# ESP32-S31 register map
Vendor: ESPRESSIF SYSTEMS (SHANGHAI) CO., LTD.; Series: ESP32 S-Series; File version: 1
CPU: RV32IMAFC r0p0, little endian, no MPU, FPU, 0 interrupt priority bits
Address unit: 32 bits
Registers are 32-bit, read-write, reset 0x0 unless marked. A register's access mark holds for its fields unless they carry their own. Offsets are from the block's base; [hi:lo] are bit positions; {n}, {i} and the like mark numbered series.

## LP_CLKCALI — LP_CLKCALI Peripheral
Base 0x20802000
Same registers: RTCLOCKCALI1 0x20803000
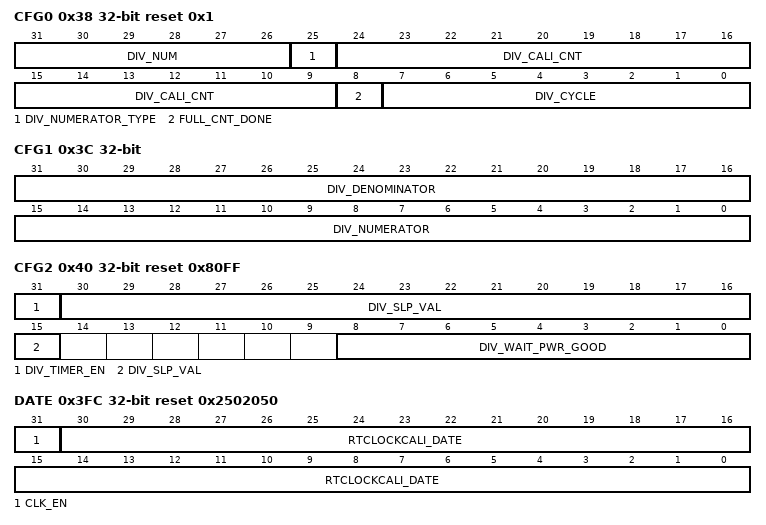
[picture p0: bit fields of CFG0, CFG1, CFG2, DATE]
0x38 CFG0 access per field reset 0x1 — need_des
  [31:26] DIV_NUM ro — need_des
  [25] DIV_NUMERATOR_TYPE ro — need_des
  [24:9] DIV_CALI_CNT ro — need_des
  [8] FULL_CNT_DONE ro — need_des
  [7:0] DIV_CYCLE rw — need_des
0x3C CFG1 ro — need_des
  [31:16] DIV_DENOMINATOR — need_des
  [15:0] DIV_NUMERATOR — need_des
0x40 CFG2 reset 0x80FF — need_des
  [31] DIV_TIMER_EN — need_des
  [30:15] DIV_SLP_VAL — need_des
  [8:0] DIV_WAIT_PWR_GOOD — need_des
0x3FC DATE reset 0x2502050 — Configure register.
  [31] CLK_EN — need_des
  [30:0] RTCLOCKCALI_DATE — need_des

## LP_TIMER — Low-power Timer
Base 0x20800000
0x00 TAR0_LOW — need_des
  [31:0] MAIN_TIMER_TAR_LOW0
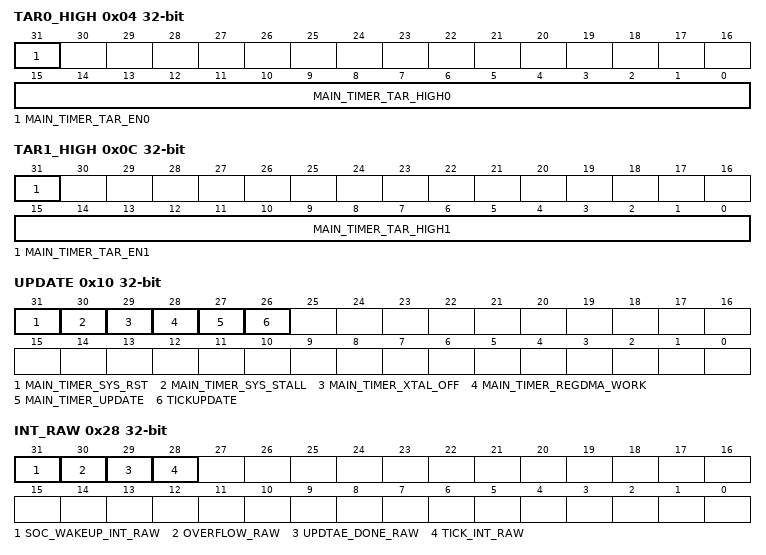
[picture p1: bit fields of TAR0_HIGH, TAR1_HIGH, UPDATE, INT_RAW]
0x04 TAR0_HIGH access per field — need_des
  [31] MAIN_TIMER_TAR_EN0 wo — need_des
  [15:0] MAIN_TIMER_TAR_HIGH0 rw — need_des
0x08 TAR1_LOW — need_des
  [31:0] MAIN_TIMER_TAR_LOW1
0x0C TAR1_HIGH access per field — need_des
  [31] MAIN_TIMER_TAR_EN1 wo — need_des
  [15:0] MAIN_TIMER_TAR_HIGH1 rw — need_des
0x10 UPDATE access per field — need_des
  [31] MAIN_TIMER_SYS_RST rw — need_des
  [30] MAIN_TIMER_SYS_STALL rw — need_des
  [29] MAIN_TIMER_XTAL_OFF rw — need_des
  [28] MAIN_TIMER_REGDMA_WORK rw — need_des
  [27] MAIN_TIMER_UPDATE wo — need_des
  [26] TICKUPDATE rw — need_des
0x14 MAIN_BUF0_LOW ro — need_des
  [31:0] MAIN_TIMER_BUF0_LOW
0x18 MAIN_BUF0_HIGH ro — need_des
  [15:0] MAIN_TIMER_BUF0_HIGH
0x1C MAIN_BUF1_LOW ro — need_des
  [31:0] MAIN_TIMER_BUF1_LOW
0x20 MAIN_BUF1_HIGH ro — need_des
  [15:0] MAIN_TIMER_BUF1_HIGH
0x24 MAIN_OVERFLOW wo — need_des
  [31] MAIN_TIMER_ALARM_LOAD
0x28 INT_RAW — need_des
  [31] SOC_WAKEUP_INT_RAW — need_des
  [30] OVERFLOW_RAW — need_des
  [29] UPDTAE_DONE_RAW — need_des
  [28] TICK_INT_RAW — need_des
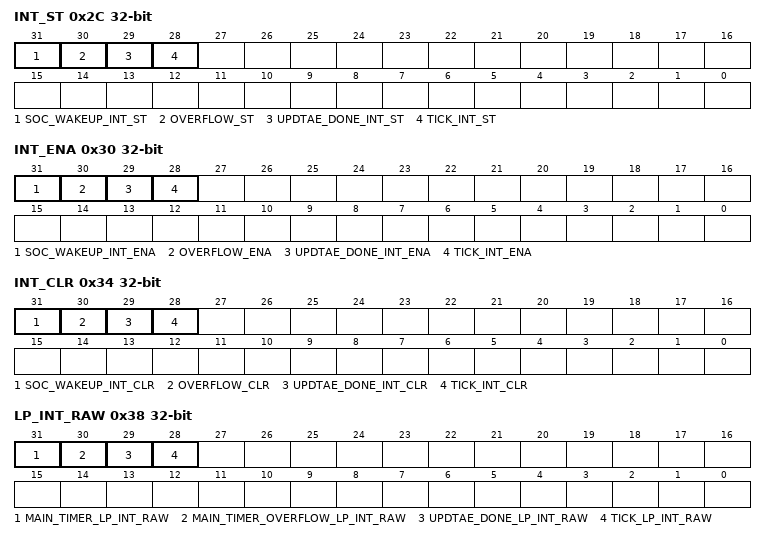
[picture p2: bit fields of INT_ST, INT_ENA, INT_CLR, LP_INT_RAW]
0x2C INT_ST ro — need_des
  [31] SOC_WAKEUP_INT_ST — need_des
  [30] OVERFLOW_ST — need_des
  [29] UPDTAE_DONE_INT_ST — need_des
  [28] TICK_INT_ST — need_des
0x30 INT_ENA — need_des
  [31] SOC_WAKEUP_INT_ENA — need_des
  [30] OVERFLOW_ENA — need_des
  [29] UPDTAE_DONE_INT_ENA — need_des
  [28] TICK_INT_ENA — need_des
0x34 INT_CLR wo — need_des
  [31] SOC_WAKEUP_INT_CLR — need_des
  [30] OVERFLOW_CLR — need_des
  [29] UPDTAE_DONE_INT_CLR — need_des
  [28] TICK_INT_CLR — need_des
0x38 LP_INT_RAW — need_des
  [31] MAIN_TIMER_LP_INT_RAW — need_des
  [30] MAIN_TIMER_OVERFLOW_LP_INT_RAW — need_des
  [29] UPDTAE_DONE_LP_INT_RAW — need_des
  [28] TICK_LP_INT_RAW — need_des
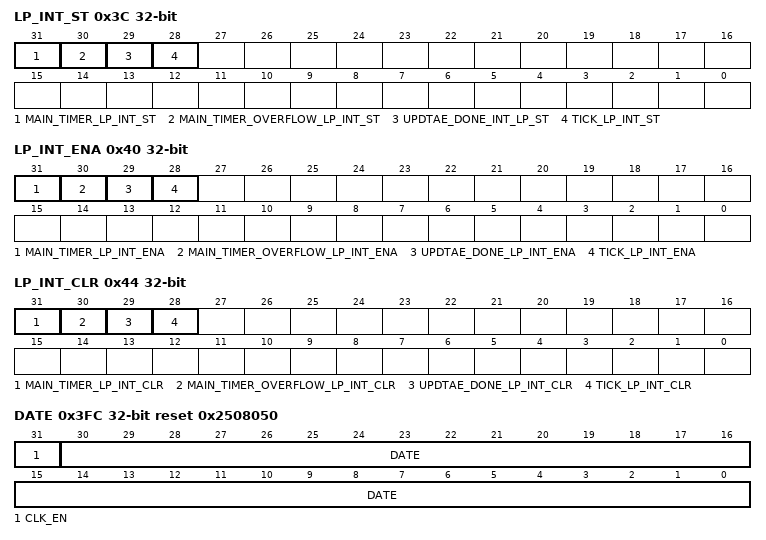
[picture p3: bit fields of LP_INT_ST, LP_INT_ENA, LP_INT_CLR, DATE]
0x3C LP_INT_ST ro — need_des
  [31] MAIN_TIMER_LP_INT_ST — need_des
  [30] MAIN_TIMER_OVERFLOW_LP_INT_ST — need_des
  [29] UPDTAE_DONE_INT_LP_ST — need_des
  [28] TICK_LP_INT_ST — need_des
0x40 LP_INT_ENA — need_des
  [31] MAIN_TIMER_LP_INT_ENA — need_des
  [30] MAIN_TIMER_OVERFLOW_LP_INT_ENA — need_des
  [29] UPDTAE_DONE_LP_INT_ENA — need_des
  [28] TICK_LP_INT_ENA — need_des
0x44 LP_INT_CLR wo — need_des
  [31] MAIN_TIMER_LP_INT_CLR — need_des
  [30] MAIN_TIMER_OVERFLOW_LP_INT_CLR — need_des
  [29] UPDTAE_DONE_LP_INT_CLR — need_des
  [28] TICK_LP_INT_CLR — need_des
0x3FC DATE reset 0x2508050 — need_des
  [31] CLK_EN — need_des
  [30:0] DATE — need_des

## LP_WDT — Low-power Watchdog Timer
Base 0x20801000
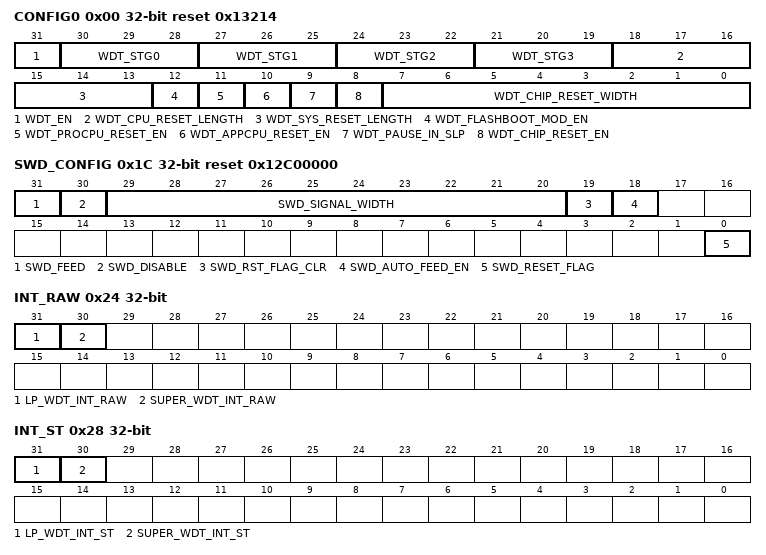
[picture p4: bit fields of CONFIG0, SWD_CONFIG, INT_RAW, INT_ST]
0x00 CONFIG0 reset 0x13214 — need_des
  [31] WDT_EN — need_des
  [30-3n:28-3n] WDT_STG{n} (n=0..3) — need_des
  [18:16] WDT_CPU_RESET_LENGTH — need_des
  [15:13] WDT_SYS_RESET_LENGTH — need_des
  [12] WDT_FLASHBOOT_MOD_EN — need_des
  [11] WDT_PROCPU_RESET_EN — need_des
  [10] WDT_APPCPU_RESET_EN — need_des
  [9] WDT_PAUSE_IN_SLP — need_des
  [8] WDT_CHIP_RESET_EN — need_des
  [7:0] WDT_CHIP_RESET_WIDTH — need_des
0x04 CONFIG1 reset 0x30D40 — need_des
  [31:0] WDT_STG0_HOLD
0x08 CONFIG2 reset 0x13880 — need_des
  [31:0] WDT_STG1_HOLD
0x0C CONFIG3 reset 0xFFF — need_des
  [31:0] WDT_STG2_HOLD
0x10 CONFIG4 reset 0xFFF — need_des
  [31:0] WDT_STG3_HOLD
0x14 FEED wo — need_des
  [31] FEED
0x18 WPROTECT — need_des
  [31:0] WDT_WKEY
0x1C SWD_CONFIG access per field reset 0x12C00000 — need_des
  [31] SWD_FEED wo — need_des
  [30] SWD_DISABLE rw — need_des
  [29:20] SWD_SIGNAL_WIDTH rw — need_des
  [19] SWD_RST_FLAG_CLR wo — need_des
  [18] SWD_AUTO_FEED_EN rw — need_des
  [0] SWD_RESET_FLAG ro — need_des
0x20 SWD_WPROTECT — need_des
  [31:0] SWD_WKEY
0x24 INT_RAW — need_des
  [31] LP_WDT_INT_RAW — need_des
  [30] SUPER_WDT_INT_RAW — need_des
0x28 INT_ST ro — need_des
  [31] LP_WDT_INT_ST — need_des
  [30] SUPER_WDT_INT_ST — need_des
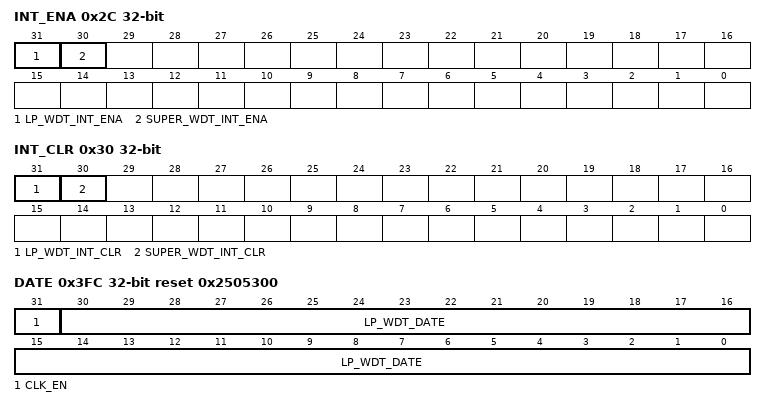
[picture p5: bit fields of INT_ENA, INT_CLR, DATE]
0x2C INT_ENA — need_des
  [31] LP_WDT_INT_ENA — need_des
  [30] SUPER_WDT_INT_ENA — need_des
0x30 INT_CLR wo — need_des
  [31] LP_WDT_INT_CLR — need_des
  [30] SUPER_WDT_INT_CLR — need_des
0x34 PAUSE_EN reset 0x80000000 — need_des
  [31] PAUSE_EN
0x3FC DATE reset 0x2505300 — need_des
  [31] CLK_EN — need_des
  [30:0] LP_WDT_DATE — need_des
